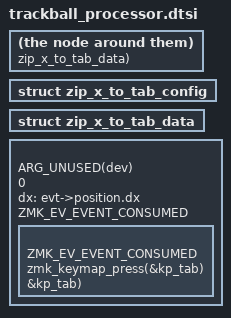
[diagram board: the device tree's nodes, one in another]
#include <zephyr.h>
#include <zmk/input.h>
#include <zmk/event_manager.h>
#include <zmk/events/position_state_changed.h>
#include <zmk/keymap.h>
#include <zmk/behavior.h>
#include <dt-bindings/zmk/keys.h>

struct zip_x_to_tab_config {
    /* no configuration for now */
};

struct zip_x_to_tab_data {
    /* placeholder for state if needed */
};

static int zip_x_to_tab_init(struct device *dev) {
    ARG_UNUSED(dev);
    return 0;
}

/* input processor callback */
static int zip_x_to_tab_process(struct device *dev,
                                struct zmk_input_event *evt,
                                struct zip_x_to_tab_config *cfg,
                                struct zip_x_to_tab_data *data) {
    if (evt->type != ZMK_INPUT_POSITION_STATE_CHANGED) {
        return ZMK_EV_EVENT_CONSUMED;
    }

    int16_t dx = evt->position.dx;
    if (dx > 0) {
        zmk_keymap_press(&kp_tab);
    } else if (dx < 0) {
        zmk_keymap_press(&kp_LSHIFT, &kp_tab);  // Shift+Tab
    }

    return ZMK_EV_EVENT_CONSUMED;
}

/* Define the processor */
ZMK_INPUT_PROCESSOR_DEFINE(zip_x_to_tab, zip_x_to_tab_process, zip_x_to_tab_init, struct zip_x_to_tab_config, struct zip_x_to_tab_data);
